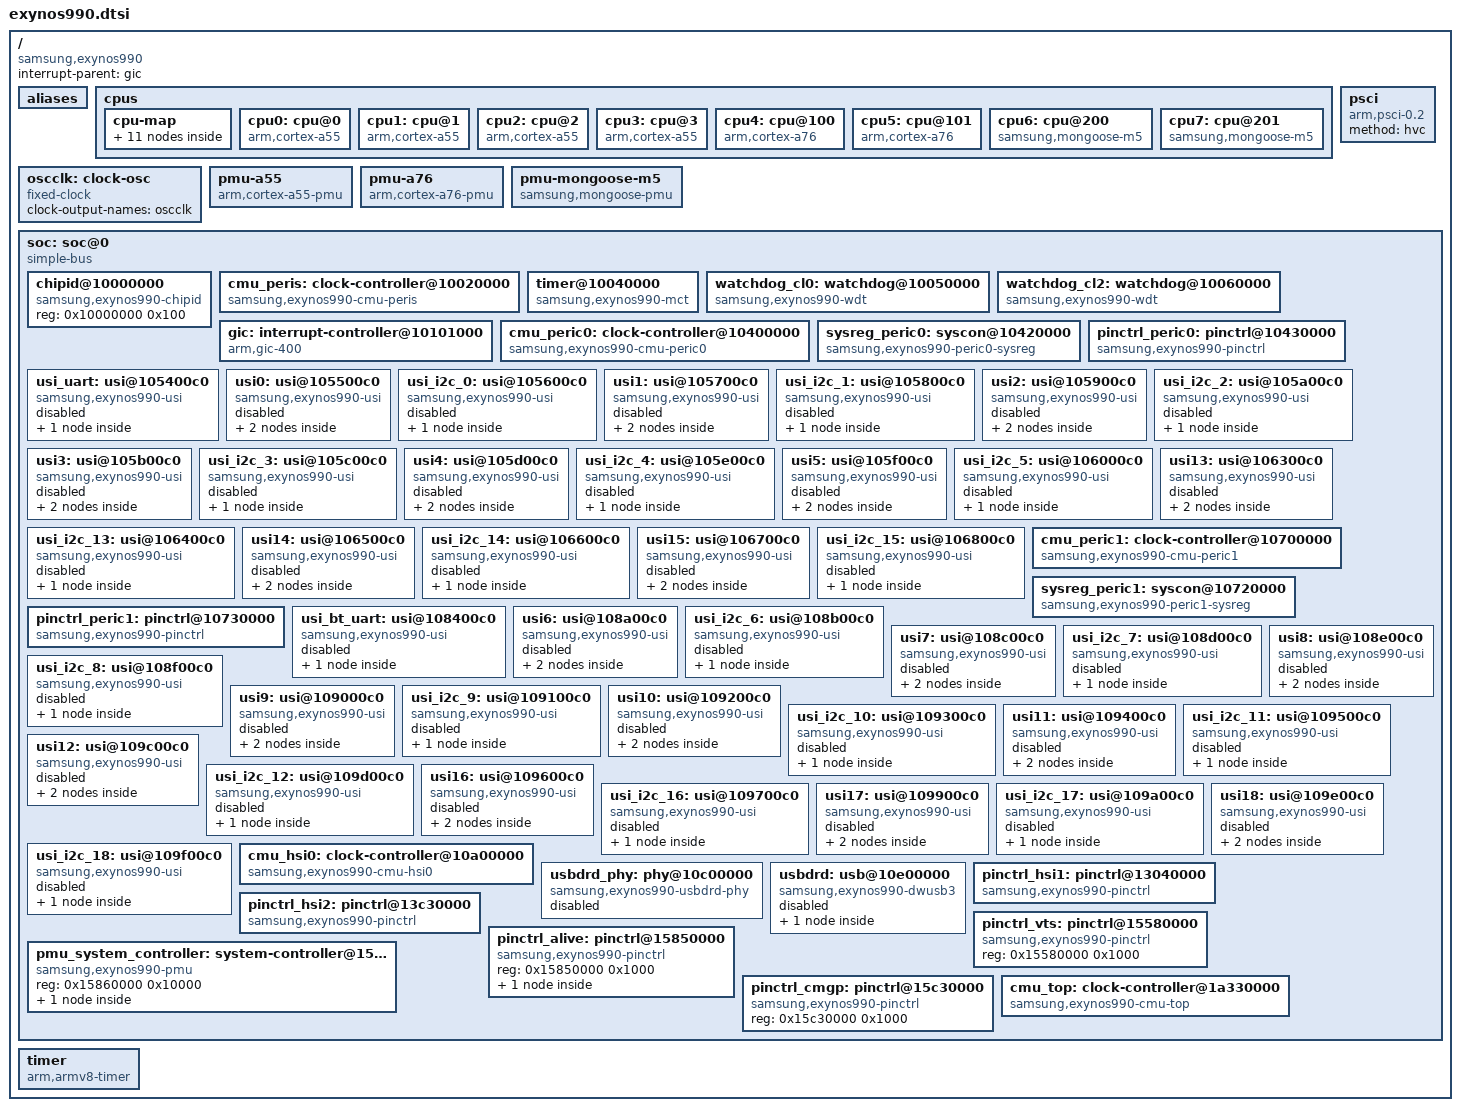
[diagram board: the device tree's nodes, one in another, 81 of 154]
// SPDX-License-Identifier: GPL-2.0 OR BSD-3-Clause
/*
 * Samsung Exynos 990 SoC device tree source
 *
 * Copyright (c) 2024, Igor Belwon <igor.belwon@mentallysanemainliners.org>
 */

#include <dt-bindings/clock/samsung,exynos990.h>
#include <dt-bindings/interrupt-controller/arm-gic.h>
#include <dt-bindings/soc/samsung,exynos-usi.h>

/ {
	compatible = "samsung,exynos990";
	#address-cells = <2>;
	#size-cells = <1>;

	interrupt-parent = <&gic>;

	aliases {
		pinctrl0 = &pinctrl_alive;
		pinctrl1 = &pinctrl_cmgp;
		pinctrl2 = &pinctrl_hsi1;
		pinctrl3 = &pinctrl_hsi2;
		pinctrl4 = &pinctrl_peric0;
		pinctrl5 = &pinctrl_peric1;
		pinctrl6 = &pinctrl_vts;
	};

	cpus {
		#address-cells = <1>;
		#size-cells = <0>;

		cpu-map {
			cluster0 {
				core0 {
					cpu = <&cpu0>;
				};

				core1 {
					cpu = <&cpu1>;
				};

				core2 {
					cpu = <&cpu2>;
				};

				core3 {
					cpu = <&cpu3>;
				};
			};

			cluster1 {
				core0 {
					cpu = <&cpu4>;
				};

				core1 {
					cpu = <&cpu5>;
				};
			};

			cluster2 {
				core0 {
					cpu = <&cpu6>;
				};

				core1 {
					cpu = <&cpu7>;
				};
			};
		};

		cpu0: cpu@0 {
			device_type = "cpu";
			compatible = "arm,cortex-a55";
			reg = <0x0>;
			enable-method = "psci";
		};

		cpu1: cpu@1 {
			device_type = "cpu";
			compatible = "arm,cortex-a55";
			reg = <0x1>;
			enable-method = "psci";
		};

		cpu2: cpu@2 {
			device_type = "cpu";
			compatible = "arm,cortex-a55";
			reg = <0x2>;
			enable-method = "psci";
		};

		cpu3: cpu@3 {
			device_type = "cpu";
			compatible = "arm,cortex-a55";
			reg = <0x3>;
			enable-method = "psci";
		};

		cpu4: cpu@100 {
			device_type = "cpu";
			compatible = "arm,cortex-a76";
			reg = <0x4>;
			enable-method = "psci";
		};

		cpu5: cpu@101 {
			device_type = "cpu";
			compatible = "arm,cortex-a76";
			reg = <0x5>;
			enable-method = "psci";
		};

		cpu6: cpu@200 {
			device_type = "cpu";
			compatible = "samsung,mongoose-m5";
			reg = <0x6>;
			enable-method = "psci";
		};

		cpu7: cpu@201 {
			device_type = "cpu";
			compatible = "samsung,mongoose-m5";
			reg = <0x7>;
			enable-method = "psci";
		};
	};

	oscclk: clock-osc {
		compatible = "fixed-clock";
		#clock-cells = <0>;
		clock-output-names = "oscclk";
	};

	pmu-a55 {
		compatible = "arm,cortex-a55-pmu";
		interrupts = <GIC_SPI 163 IRQ_TYPE_LEVEL_HIGH>,
			     <GIC_SPI 164 IRQ_TYPE_LEVEL_HIGH>,
			     <GIC_SPI 165 IRQ_TYPE_LEVEL_HIGH>,
			     <GIC_SPI 166 IRQ_TYPE_LEVEL_HIGH>;

		interrupt-affinity = <&cpu0>,
				     <&cpu1>,
				     <&cpu2>,
				     <&cpu3>;
	};

	pmu-a76 {
		compatible = "arm,cortex-a76-pmu";
		interrupts = <GIC_SPI 167 IRQ_TYPE_LEVEL_HIGH>,
			     <GIC_SPI 168 IRQ_TYPE_LEVEL_HIGH>;

		interrupt-affinity = <&cpu4>,
				     <&cpu5>;
	};

	pmu-mongoose-m5 {
		compatible = "samsung,mongoose-pmu";
		interrupts = <GIC_SPI 180 IRQ_TYPE_LEVEL_HIGH>,
			     <GIC_SPI 181 IRQ_TYPE_LEVEL_HIGH>;

		interrupt-affinity = <&cpu6>,
				     <&cpu7>;
	};

	psci {
		compatible = "arm,psci-0.2";
		method = "hvc";
	};

	soc: soc@0 {
		compatible = "simple-bus";
		ranges = <0x0 0x0 0x0 0x20000000>;

		#address-cells = <1>;
		#size-cells = <1>;

		chipid@10000000 {
			compatible = "samsung,exynos990-chipid",
				     "samsung,exynos850-chipid";
			reg = <0x10000000 0x100>;
		};

		cmu_peris: clock-controller@10020000 {
			compatible = "samsung,exynos990-cmu-peris";
			reg = <0x10020000 0x8000>;
			#clock-cells = <1>;

			clocks = <&oscclk>,
				 <&cmu_top CLK_DOUT_CMU_PERIS_BUS>;
			clock-names = "oscclk", "bus";
		};

		timer@10040000 {
			compatible = "samsung,exynos990-mct",
				     "samsung,exynos4210-mct";
			reg = <0x10040000 0x800>;
			clocks = <&oscclk>, <&cmu_peris CLK_GOUT_PERIS_MCT_PCLK>;
			clock-names = "fin_pll", "mct";
			interrupts = <GIC_SPI 466 IRQ_TYPE_LEVEL_HIGH>,
				     <GIC_SPI 467 IRQ_TYPE_LEVEL_HIGH>,
				     <GIC_SPI 468 IRQ_TYPE_LEVEL_HIGH>,
				     <GIC_SPI 469 IRQ_TYPE_LEVEL_HIGH>,
				     <GIC_SPI 470 IRQ_TYPE_LEVEL_HIGH>,
				     <GIC_SPI 471 IRQ_TYPE_LEVEL_HIGH>,
				     <GIC_SPI 472 IRQ_TYPE_LEVEL_HIGH>,
				     <GIC_SPI 473 IRQ_TYPE_LEVEL_HIGH>,
				     <GIC_SPI 474 IRQ_TYPE_LEVEL_HIGH>,
				     <GIC_SPI 475 IRQ_TYPE_LEVEL_HIGH>,
				     <GIC_SPI 476 IRQ_TYPE_LEVEL_HIGH>,
				     <GIC_SPI 477 IRQ_TYPE_LEVEL_HIGH>;
		};

		watchdog_cl0: watchdog@10050000 {
			compatible = "samsung,exynos990-wdt";
			reg = <0x10050000 0x100>;
			interrupts = <GIC_SPI 464 IRQ_TYPE_LEVEL_HIGH>;
			clocks = <&cmu_peris CLK_GOUT_PERIS_WDT_CLUSTER0_PCLK>,
				 <&oscclk>;
			clock-names = "watchdog",
				      "watchdog_src";
			samsung,syscon-phandle = <&pmu_system_controller>;
			samsung,cluster-index = <0>;
		};

		watchdog_cl2: watchdog@10060000 {
			compatible = "samsung,exynos990-wdt";
			reg = <0x10060000 0x100>;
			interrupts = <GIC_SPI 465 IRQ_TYPE_LEVEL_HIGH>;
			clocks = <&cmu_peris CLK_GOUT_PERIS_WDT_CLUSTER2_PCLK>,
				 <&oscclk>;
			clock-names = "watchdog",
				      "watchdog_src";
			samsung,syscon-phandle = <&pmu_system_controller>;
			samsung,cluster-index = <2>;
		};

		gic: interrupt-controller@10101000 {
			compatible = "arm,gic-400";
			reg = <0x10101000 0x1000>,
			      <0x10102000 0x1000>,
			      <0x10104000 0x2000>,
			      <0x10106000 0x2000>;
			#interrupt-cells = <3>;
			interrupt-controller;
			interrupts = <GIC_PPI 9 (GIC_CPU_MASK_SIMPLE(8) |
						 IRQ_TYPE_LEVEL_HIGH)>;
			#address-cells = <0>;
			#size-cells = <1>;
		};

		cmu_peric0: clock-controller@10400000 {
			compatible = "samsung,exynos990-cmu-peric0";
			reg = <0x10400000 0x8000>;
			#clock-cells = <1>;

			clocks = <&oscclk>,
				 <&cmu_top CLK_DOUT_CMU_PERIC0_BUS>,
				 <&cmu_top CLK_DOUT_CMU_PERIC0_IP>;
			clock-names = "oscclk", "bus", "ip";
		};

		sysreg_peric0: syscon@10420000 {
			compatible = "samsung,exynos990-peric0-sysreg", "syscon";
			reg = <0x10420000 0x10000>;
			clocks = <&cmu_peric0 CLK_GOUT_PERIC0_SYSREG_PCLK>;
		};

		pinctrl_peric0: pinctrl@10430000 {
			compatible = "samsung,exynos990-pinctrl";
			reg = <0x10430000 0x1000>;
			interrupts = <GIC_SPI 392 IRQ_TYPE_LEVEL_HIGH>;
		};

		usi_uart: usi@105400c0 {
			compatible = "samsung,exynos990-usi", "samsung,exynos850-usi";
			reg = <0x105400c0 0x20>;
			ranges;
			#address-cells = <1>;
			#size-cells = <1>;
			clocks = <&cmu_peric0 CLK_GOUT_PERIC0_TOP0_PCLK_4>,
				 <&cmu_peric0 CLK_GOUT_PERIC0_TOP0_IPCLK_4>;
			clock-names = "pclk", "ipclk";
			samsung,sysreg = <&sysreg_peric0 0x1000>;
			samsung,mode = <USI_MODE_UART>;
			status = "disabled";

			serial_0: serial@10540000 {
				compatible = "samsung,exynos990-uart",
					     "samsung,exynos8895-uart";
				reg = <0x10540000 0xc0>;
				clocks = <&cmu_peric0 CLK_GOUT_PERIC0_TOP0_PCLK_4>,
					 <&cmu_peric0 CLK_GOUT_PERIC0_TOP0_IPCLK_4>;
				clock-names = "uart", "clk_uart_baud0";
				interrupts = <GIC_SPI 391 IRQ_TYPE_LEVEL_HIGH>;
				pinctrl-0 = <&uart0_bus>;
				pinctrl-names = "default";
				samsung,uart-fifosize = <256>;
				status = "disabled";
			};
		};

		usi0: usi@105500c0 {
			compatible = "samsung,exynos990-usi", "samsung,exynos850-usi";
			reg = <0x105500c0 0x20>;
			ranges;
			#address-cells = <1>;
			#size-cells = <1>;
			clocks = <&cmu_peric0 CLK_GOUT_PERIC0_TOP0_PCLK_5>,
				 <&cmu_peric0 CLK_GOUT_PERIC0_TOP0_IPCLK_5>;
			clock-names = "pclk", "ipclk";
			samsung,sysreg = <&sysreg_peric0 0x1004>;
			status = "disabled";

			hsi2c_0: i2c@10550000 {
				compatible = "samsung,exynos990-hsi2c",
					     "samsung,exynosautov9-hsi2c";
				reg = <0x10550000 0xc0>;
				#address-cells = <1>;
				#size-cells = <0>;
				clocks = <&cmu_peric0 CLK_GOUT_PERIC0_TOP0_IPCLK_5>,
					 <&cmu_peric0 CLK_GOUT_PERIC0_TOP0_PCLK_5>;
				clock-names = "hsi2c", "hsi2c_pclk";
				interrupts = <GIC_SPI 399 IRQ_TYPE_LEVEL_HIGH>;
				pinctrl-0 = <&hsi2c0_bus>;
				pinctrl-names = "default";
				status = "disabled";
			};

			serial_2: serial@10550000 {
				compatible = "samsung,exynos990-uart",
					     "samsung,exynos8895-uart";
				reg = <0x10550000 0xc0>;
				clocks = <&cmu_peric0 CLK_GOUT_PERIC0_TOP0_PCLK_5>,
					 <&cmu_peric0 CLK_GOUT_PERIC0_TOP0_IPCLK_5>;
				clock-names = "uart", "clk_uart_baud0";
				interrupts = <GIC_SPI 399 IRQ_TYPE_LEVEL_HIGH>;
				pinctrl-0 = <&uart2_bus_single>;
				pinctrl-names = "default";
				samsung,uart-fifosize = <64>;
				status = "disabled";
			};
		};

		usi_i2c_0: usi@105600c0 {
			compatible = "samsung,exynos990-usi", "samsung,exynos850-usi";
			reg = <0x105600c0 0x20>;
			ranges;
			#address-cells = <1>;
			#size-cells = <1>;
			clocks = <&cmu_peric0 CLK_GOUT_PERIC0_TOP0_PCLK_6>,
				 <&cmu_peric0 CLK_GOUT_PERIC0_TOP0_IPCLK_6>;
			clock-names = "pclk", "ipclk";
			samsung,sysreg = <&sysreg_peric0 0x1008>;
			samsung,mode = <USI_MODE_I2C>;
			status = "disabled";

			hsi2c_1: i2c@10560000 {
				compatible = "samsung,exynos990-hsi2c",
					     "samsung,exynosautov9-hsi2c";
				reg = <0x10560000 0xc0>;
				#address-cells = <1>;
				#size-cells = <0>;
				clocks = <&cmu_peric0 CLK_GOUT_PERIC0_TOP0_IPCLK_6>,
					 <&cmu_peric0 CLK_GOUT_PERIC0_TOP0_PCLK_6>;
				clock-names = "hsi2c", "hsi2c_pclk";
				interrupts = <GIC_SPI 398 IRQ_TYPE_LEVEL_HIGH>;
				pinctrl-0 = <&hsi2c1_bus>;
				pinctrl-names = "default";
				status = "disabled";
			};
		};

		usi1: usi@105700c0 {
			compatible = "samsung,exynos990-usi", "samsung,exynos850-usi";
			reg = <0x105700c0 0x20>;
			ranges;
			#address-cells = <1>;
			#size-cells = <1>;
			clocks = <&cmu_peric0 CLK_GOUT_PERIC0_TOP0_PCLK_7>,
				 <&cmu_peric0 CLK_GOUT_PERIC0_TOP0_IPCLK_7>;
			clock-names = "pclk", "ipclk";
			samsung,sysreg = <&sysreg_peric0 0x100c>;
			status = "disabled";


			hsi2c_2: i2c@10570000 {
				compatible = "samsung,exynos990-hsi2c",
					     "samsung,exynosautov9-hsi2c";
				reg = <0x10570000 0xc0>;
				#address-cells = <1>;
				#size-cells = <0>;
				clocks = <&cmu_peric0 CLK_GOUT_PERIC0_TOP0_IPCLK_7>,
					 <&cmu_peric0 CLK_GOUT_PERIC0_TOP0_PCLK_7>;
				clock-names = "hsi2c", "hsi2c_pclk";
				interrupts = <GIC_SPI 401 IRQ_TYPE_LEVEL_HIGH>;
				pinctrl-0 = <&hsi2c2_bus>;
				pinctrl-names = "default";
				status = "disabled";
			};

			serial_3: serial@10570000 {
				compatible = "samsung,exynos990-uart",
					     "samsung,exynos8895-uart";
				reg = <0x10570000 0xc0>;
				clocks = <&cmu_peric0 CLK_GOUT_PERIC0_TOP0_PCLK_7>,
					 <&cmu_peric0 CLK_GOUT_PERIC0_TOP0_IPCLK_7>;
				clock-names = "uart", "clk_uart_baud0";
				interrupts = <GIC_SPI 401 IRQ_TYPE_LEVEL_HIGH>;
				pinctrl-0 = <&uart3_bus_single>;
				pinctrl-names = "default";
				samsung,uart-fifosize = <64>;
				status = "disabled";
			};
		};

		usi_i2c_1: usi@105800c0 {
			compatible = "samsung,exynos990-usi", "samsung,exynos850-usi";
			reg = <0x105800c0 0x20>;
			ranges;
			#address-cells = <1>;
			#size-cells = <1>;
			clocks = <&cmu_peric0 CLK_GOUT_PERIC0_TOP0_PCLK_8>,
				 <&cmu_peric0 CLK_GOUT_PERIC0_TOP0_IPCLK_8>;
			clock-names = "pclk", "ipclk";
			samsung,sysreg = <&sysreg_peric0 0x1010>;
			samsung,mode = <USI_MODE_I2C>;
			status = "disabled";

			hsi2c_3: i2c@10580000 {
				compatible = "samsung,exynos990-hsi2c",
					     "samsung,exynosautov9-hsi2c";
				reg = <0x10580000 0xc0>;
				#address-cells = <1>;
				#size-cells = <0>;
				clocks = <&cmu_peric0 CLK_GOUT_PERIC0_TOP0_IPCLK_8>,
					 <&cmu_peric0 CLK_GOUT_PERIC0_TOP0_PCLK_8>;
				clock-names = "hsi2c", "hsi2c_pclk";
				interrupts = <GIC_SPI 400 IRQ_TYPE_LEVEL_HIGH>;
				pinctrl-0 = <&hsi2c3_bus>;
				pinctrl-names = "default";
				status = "disabled";
			};
		};

		usi2: usi@105900c0 {
			compatible = "samsung,exynos990-usi", "samsung,exynos850-usi";
			reg = <0x105900c0 0x20>;
			ranges;
			#address-cells = <1>;
			#size-cells = <1>;
			clocks = <&cmu_peric0 CLK_GOUT_PERIC0_TOP0_PCLK_9>,
				 <&cmu_peric0 CLK_GOUT_PERIC0_TOP0_IPCLK_9>;
			clock-names = "pclk", "ipclk";
			samsung,sysreg = <&sysreg_peric0 0x1014>;
			status = "disabled";

			hsi2c_4: i2c@10590000 {
				compatible = "samsung,exynos990-hsi2c",
					     "samsung,exynosautov9-hsi2c";
				reg = <0x10590000 0xc0>;
				#address-cells = <1>;
				#size-cells = <0>;
				clocks = <&cmu_peric0 CLK_GOUT_PERIC0_TOP0_IPCLK_9>,
					 <&cmu_peric0 CLK_GOUT_PERIC0_TOP0_PCLK_9>;
				clock-names = "hsi2c", "hsi2c_pclk";
				interrupts = <GIC_SPI 403 IRQ_TYPE_LEVEL_HIGH>;
				pinctrl-0 = <&hsi2c4_bus>;
				pinctrl-names = "default";
				status = "disabled";
			};

			serial_4: serial@10590000 {
				compatible = "samsung,exynos990-uart",
					     "samsung,exynos8895-uart";
				reg = <0x10590000 0xc0>;
				clocks = <&cmu_peric0 CLK_GOUT_PERIC0_TOP0_PCLK_9>,
					 <&cmu_peric0 CLK_GOUT_PERIC0_TOP0_IPCLK_9>;
				clock-names = "uart", "clk_uart_baud0";
				interrupts = <GIC_SPI 403 IRQ_TYPE_LEVEL_HIGH>;
				pinctrl-0 = <&uart4_bus_single>;
				pinctrl-names = "default";
				samsung,uart-fifosize = <64>;
				status = "disabled";
			};
		};

		usi_i2c_2: usi@105a00c0 {
			compatible = "samsung,exynos990-usi", "samsung,exynos850-usi";
			reg = <0x105a00c0 0x20>;
			ranges;
			#address-cells = <1>;
			#size-cells = <1>;
			clocks = <&cmu_peric0 CLK_GOUT_PERIC0_TOP0_PCLK_10>,
				 <&cmu_peric0 CLK_GOUT_PERIC0_TOP0_IPCLK_10>;
			clock-names = "pclk", "ipclk";
			samsung,sysreg = <&sysreg_peric0 0x1018>;
			samsung,mode = <USI_MODE_I2C>;
			status = "disabled";

			hsi2c_5: i2c@105a0000 {
				compatible = "samsung,exynos990-hsi2c",
					     "samsung,exynosautov9-hsi2c";
				reg = <0x105a0000 0xc0>;
				#address-cells = <1>;
				#size-cells = <0>;
				clocks = <&cmu_peric0 CLK_GOUT_PERIC0_TOP0_IPCLK_10>,
					 <&cmu_peric0 CLK_GOUT_PERIC0_TOP0_PCLK_10>;
				clock-names = "hsi2c", "hsi2c_pclk";
				interrupts = <GIC_SPI 402 IRQ_TYPE_LEVEL_HIGH>;
				pinctrl-0 = <&hsi2c5_bus>;
				pinctrl-names = "default";
				status = "disabled";
			};
		};

		usi3: usi@105b00c0 {
			compatible = "samsung,exynos990-usi", "samsung,exynos850-usi";
			reg = <0x105b00c0 0x20>;
			ranges;
			#address-cells = <1>;
			#size-cells = <1>;
			clocks = <&cmu_peric0 CLK_GOUT_PERIC0_TOP0_PCLK_11>,
				 <&cmu_peric0 CLK_GOUT_PERIC0_TOP0_IPCLK_11>;
			clock-names = "pclk", "ipclk";
			samsung,sysreg = <&sysreg_peric0 0x101c>;
			status = "disabled";

			hsi2c_6: i2c@105b0000 {
				compatible = "samsung,exynos990-hsi2c",
					     "samsung,exynosautov9-hsi2c";
				reg = <0x105b0000 0xc0>;
				#address-cells = <1>;
				#size-cells = <0>;
				clocks = <&cmu_peric0 CLK_GOUT_PERIC0_TOP0_IPCLK_11>,
					 <&cmu_peric0 CLK_GOUT_PERIC0_TOP0_PCLK_11>;
				clock-names = "hsi2c", "hsi2c_pclk";
				interrupts = <GIC_SPI 405 IRQ_TYPE_LEVEL_HIGH>;
				pinctrl-0 = <&hsi2c6_bus>;
				pinctrl-names = "default";
				status = "disabled";
			};

			serial_5: serial@105b0000 {
				compatible = "samsung,exynos990-uart",
					     "samsung,exynos8895-uart";
				reg = <0x105b0000 0xc0>;
				clocks = <&cmu_peric0 CLK_GOUT_PERIC0_TOP0_PCLK_11>,
					 <&cmu_peric0 CLK_GOUT_PERIC0_TOP0_IPCLK_11>;
				clock-names = "uart", "clk_uart_baud0";
				interrupts = <GIC_SPI 405 IRQ_TYPE_LEVEL_HIGH>;
				pinctrl-0 = <&uart5_bus_single>;
				pinctrl-names = "default";
				samsung,uart-fifosize = <64>;
				status = "disabled";
			};
		};

		usi_i2c_3: usi@105c00c0 {
			compatible = "samsung,exynos990-usi", "samsung,exynos850-usi";
			reg = <0x105c00c0 0x20>;
			ranges;
			#address-cells = <1>;
			#size-cells = <1>;
			clocks = <&cmu_peric0 CLK_GOUT_PERIC0_TOP0_PCLK_12>,
				 <&cmu_peric0 CLK_GOUT_PERIC0_TOP0_IPCLK_12>;
			clock-names = "pclk", "ipclk";
			samsung,sysreg = <&sysreg_peric0 0x1020>;
			samsung,mode = <USI_MODE_I2C>;
			status = "disabled";

			hsi2c_7: i2c@105c0000 {
				compatible = "samsung,exynos990-hsi2c",
					     "samsung,exynosautov9-hsi2c";
				reg = <0x105c0000 0xc0>;
				#address-cells = <1>;
				#size-cells = <0>;
				clocks = <&cmu_peric0 CLK_GOUT_PERIC0_TOP0_IPCLK_12>,
					 <&cmu_peric0 CLK_GOUT_PERIC0_TOP0_PCLK_12>;
				clock-names = "hsi2c", "hsi2c_pclk";
				interrupts = <GIC_SPI 404 IRQ_TYPE_LEVEL_HIGH>;
				pinctrl-0 = <&hsi2c7_bus>;
				pinctrl-names = "default";
				status = "disabled";
			};
		};

		usi4: usi@105d00c0 {
			compatible = "samsung,exynos990-usi", "samsung,exynos850-usi";
			reg = <0x105d00c0 0x20>;
			ranges;
			#address-cells = <1>;
			#size-cells = <1>;
			clocks = <&cmu_peric0 CLK_GOUT_PERIC0_TOP0_PCLK_13>,
				 <&cmu_peric0 CLK_GOUT_PERIC0_TOP0_IPCLK_13>;
			clock-names = "pclk", "ipclk";
			samsung,sysreg = <&sysreg_peric0 0x1024>;
			status = "disabled";

			hsi2c_8: i2c@105d0000 {
				compatible = "samsung,exynos990-hsi2c",
					     "samsung,exynosautov9-hsi2c";
				reg = <0x105d0000 0xc0>;
				#address-cells = <1>;
				#size-cells = <0>;
				clocks = <&cmu_peric0 CLK_GOUT_PERIC0_TOP0_IPCLK_13>,
					 <&cmu_peric0 CLK_GOUT_PERIC0_TOP0_PCLK_13>;
				clock-names = "hsi2c", "hsi2c_pclk";
				interrupts = <GIC_SPI 407 IRQ_TYPE_LEVEL_HIGH>;
				pinctrl-0 = <&hsi2c8_bus>;
				pinctrl-names = "default";
				status = "disabled";
			};

			serial_6: serial@105d0000 {
				compatible = "samsung,exynos990-uart",
					     "samsung,exynos8895-uart";
				reg = <0x105d0000 0xc0>;
				clocks = <&cmu_peric0 CLK_GOUT_PERIC0_TOP0_PCLK_13>,
					 <&cmu_peric0 CLK_GOUT_PERIC0_TOP0_IPCLK_13>;
				clock-names = "uart", "clk_uart_baud0";
				interrupts = <GIC_SPI 407 IRQ_TYPE_LEVEL_HIGH>;
				pinctrl-0 = <&uart6_bus_single>;
				pinctrl-names = "default";
				samsung,uart-fifosize = <64>;
				status = "disabled";
			};
		};

		usi_i2c_4: usi@105e00c0 {
			compatible = "samsung,exynos990-usi", "samsung,exynos850-usi";
			reg = <0x105e00c0 0x20>;
			ranges;
			#address-cells = <1>;
			#size-cells = <1>;
			clocks = <&cmu_peric0 CLK_GOUT_PERIC0_TOP0_PCLK_14>,
				 <&cmu_peric0 CLK_GOUT_PERIC0_TOP0_IPCLK_14>;
			clock-names = "pclk", "ipclk";
			samsung,sysreg = <&sysreg_peric0 0x1028>;
			samsung,mode = <USI_MODE_I2C>;
			status = "disabled";

			hsi2c_9: i2c@105e0000 {
				compatible = "samsung,exynos990-hsi2c",
					     "samsung,exynosautov9-hsi2c";
				reg = <0x105e0000 0xc0>;
				#address-cells = <1>;
				#size-cells = <0>;
				clocks = <&cmu_peric0 CLK_GOUT_PERIC0_TOP0_IPCLK_14>,
					 <&cmu_peric0 CLK_GOUT_PERIC0_TOP0_PCLK_14>;
				clock-names = "hsi2c", "hsi2c_pclk";
				interrupts = <GIC_SPI 406 IRQ_TYPE_LEVEL_HIGH>;
				pinctrl-0 = <&hsi2c9_bus>;
				pinctrl-names = "default";
				status = "disabled";
			};
		};

		usi5: usi@105f00c0 {
			compatible = "samsung,exynos990-usi", "samsung,exynos850-usi";
			reg = <0x105f00c0 0x20>;
			ranges;
			#address-cells = <1>;
			#size-cells = <1>;
			clocks = <&cmu_peric0 CLK_GOUT_PERIC0_TOP0_PCLK_15>,
				 <&cmu_peric0 CLK_GOUT_PERIC0_TOP0_IPCLK_15>;
			clock-names = "pclk", "ipclk";
			samsung,sysreg = <&sysreg_peric0 0x102c>;
			status = "disabled";

			hsi2c_10: i2c@105f0000 {
				compatible = "samsung,exynos990-hsi2c",
					     "samsung,exynosautov9-hsi2c";
				reg = <0x105f0000 0xc0>;
				#address-cells = <1>;
				#size-cells = <0>;
				clocks = <&cmu_peric0 CLK_GOUT_PERIC0_TOP0_IPCLK_15>,
					 <&cmu_peric0 CLK_GOUT_PERIC0_TOP0_PCLK_15>;
				clock-names = "hsi2c", "hsi2c_pclk";
				interrupts = <GIC_SPI 409 IRQ_TYPE_LEVEL_HIGH>;
				pinctrl-0 = <&hsi2c10_bus>;
				pinctrl-names = "default";
				status = "disabled";
			};

			serial_7: serial@105f0000 {
				compatible = "samsung,exynos990-uart",
					     "samsung,exynos8895-uart";
				reg = <0x105f0000 0xc0>;
				clocks = <&cmu_peric0 CLK_GOUT_PERIC0_TOP0_PCLK_15>,
					 <&cmu_peric0 CLK_GOUT_PERIC0_TOP0_IPCLK_15>;
				clock-names = "uart", "clk_uart_baud0";
				interrupts = <GIC_SPI 409 IRQ_TYPE_LEVEL_HIGH>;
				pinctrl-0 = <&uart7_bus_single>;
				pinctrl-names = "default";
				samsung,uart-fifosize = <64>;
				status = "disabled";
			};
		};

		usi_i2c_5: usi@106000c0 {
			compatible = "samsung,exynos990-usi", "samsung,exynos850-usi";
			reg = <0x106000c0 0x20>;
			rsnges;
			#address-cells = <1>;
			#size-cells = <1>;
			clocks = <&cmu_peric0 CLK_GOUT_PERIC0_TOP1_PCLK_0>,
				 <&cmu_peric0 CLK_GOUT_PERIC0_TOP1_IPCLK_0>;
			clock-names = "pclk", "ipclk";
			samsung,sysreg = <&sysreg_peric0 0x1030>;
			samsung,mode = <USI_MODE_I2C>;
			status = "disabled";

			hsi2c_11: i2c@10600000 {
				compatible = "samsung,exynos990-hsi2c",
					     "samsung,exynosautov9-hsi2c";
				reg = <0x10600000 0xc0>;
				#address-cells = <1>;
				#size-cells = <0>;
				interrupts = <GIC_SPI 408 IRQ_TYPE_LEVEL_HIGH>;
				clocks = <&cmu_peric0 CLK_GOUT_PERIC0_TOP1_IPCLK_0>,
					 <&cmu_peric0 CLK_GOUT_PERIC0_TOP1_PCLK_0>;
				clock-names = "hsi2c", "hsi2c_pclk";
				pinctrl-0 = <&hsi2c11_bus>;
				pinctrl-names = "default";
				status = "disabled";
			};
		};

		usi13: usi@106300c0 {
			compatible = "samsung,exynos990-usi", "samsung,exynos850-usi";
			reg = <0x106300c0 0x20>;
			ranges;
			#address-cells = <1>;
			#size-cells = <1>;
			clocks = <&cmu_peric0 CLK_GOUT_PERIC0_TOP1_PCLK_3>,
				 <&cmu_peric0 CLK_GOUT_PERIC0_TOP1_IPCLK_3>;
			clock-names = "pclk", "ipclk";
			samsung,sysreg = <&sysreg_peric0 0x103c>;
			status = "disabled";

			hsi2c_26: i2c@10630000 {
				compatible = "samsung,exynos990-hsi2c",
					     "samsung,exynosautov9-hsi2c";
				reg = <0x10630000 0xc0>;
				#address-cells = <1>;
				#size-cells = <0>;
				clocks = <&cmu_peric0 CLK_GOUT_PERIC0_TOP1_IPCLK_3>,
					 <&cmu_peric0 CLK_GOUT_PERIC0_TOP1_PCLK_3>;
				clock-names = "hsi2c", "hsi2c_pclk";
				interrupts = <GIC_SPI 411 IRQ_TYPE_LEVEL_HIGH>;
				pinctrl-0 = <&hsi2c26_bus>;
				pinctrl-names = "default";
				status = "disabled";
			};

			serial_15: serial@10630000 {
				compatible = "samsung,exynos990-uart",
					     "samsung,exynos8895-uart";
				reg = <0x10630000 0xc0>;
				clocks = <&cmu_peric0 CLK_GOUT_PERIC0_TOP1_PCLK_3>,
					 <&cmu_peric0 CLK_GOUT_PERIC0_TOP1_IPCLK_3>;
				clock-names = "uart", "clk_uart_baud0";
				interrupts = <GIC_SPI 411 IRQ_TYPE_LEVEL_HIGH>;
				pinctrl-0 = <&uart15_bus_single>;
				pinctrl-names = "default";
				samsung,uart-fifosize = <64>;
				status = "disabled";
			};
		};

		usi_i2c_13: usi@106400c0 {
			compatible = "samsung,exynos990-usi", "samsung,exynos850-usi";
			reg = <0x106400c0 0x20>;
			ranges;
			#address-cells = <1>;
			#size-cells = <1>;
			clocks = <&cmu_peric0 CLK_GOUT_PERIC0_TOP1_PCLK_4>,
				 <&cmu_peric0 CLK_GOUT_PERIC0_TOP1_IPCLK_4>;
			clock-names = "pclk", "ipclk";
			samsung,sysreg = <&sysreg_peric0 0x1040>;
			samsung,mode = <USI_MODE_I2C>;
			status = "disabled";

			hsi2c_27: i2c@10640000 {
				compatible = "samsung,exynos990-hsi2c",
					     "samsung,exynosautov9-hsi2c";
				reg = <0x10640000 0xc0>;
				#address-cells = <1>;
				#size-cells = <0>;
				clocks = <&cmu_peric0 CLK_GOUT_PERIC0_TOP1_IPCLK_4>,
					 <&cmu_peric0 CLK_GOUT_PERIC0_TOP1_PCLK_4>;
				clock-names = "hsi2c", "hsi2c_pclk";
				interrupts = <GIC_SPI 410 IRQ_TYPE_LEVEL_HIGH>;
				pinctrl-0 = <&hsi2c27_bus>;
				pinctrl-names = "default";
				status = "disabled";
			};
		};

		usi14: usi@106500c0 {
			compatible = "samsung,exynos990-usi", "samsung,exynos850-usi";
			reg = <0x106500c0 0x20>;
			ranges;
			#address-cells = <1>;
			#size-cells = <1>;
			clocks = <&cmu_peric0 CLK_GOUT_PERIC0_TOP1_PCLK_5>,
				 <&cmu_peric0 CLK_GOUT_PERIC0_TOP1_IPCLK_5>;
			clock-names = "pclk", "ipclk";
			samsung,sysreg = <&sysreg_peric0 0x1044>;
			status = "disabled";

			hsi2c_28: i2c@10650000 {
				compatible = "samsung,exynos990-hsi2c",
					     "samsung,exynosautov9-hsi2c";
				reg = <0x10650000 0xc0>;
				#address-cells = <1>;
				#size-cells = <0>;
				clocks = <&cmu_peric0 CLK_GOUT_PERIC0_TOP1_IPCLK_5>,
					 <&cmu_peric0 CLK_GOUT_PERIC0_TOP1_PCLK_5>;
				clock-names = "hsi2c", "hsi2c_pclk";
				interrupts = <GIC_SPI 413 IRQ_TYPE_LEVEL_HIGH>;
				pinctrl-0 = <&hsi2c28_bus>;
				pinctrl-names = "default";
				status = "disabled";
			};

			serial_16: serial@10650000 {
				compatible = "samsung,exynos990-uart",
					     "samsung,exynos8895-uart";
				reg = <0x10650000 0xc0>;
				clocks = <&cmu_peric0 CLK_GOUT_PERIC0_TOP1_PCLK_5>,
					 <&cmu_peric0 CLK_GOUT_PERIC0_TOP1_IPCLK_5>;
				clock-names = "uart", "clk_uart_baud0";
				interrupts = <GIC_SPI 413 IRQ_TYPE_LEVEL_HIGH>;
				pinctrl-0 = <&uart16_bus_single>;
				pinctrl-names = "default";
				samsung,uart-fifosize = <64>;
				status = "disabled";
			};
		};

		usi_i2c_14: usi@106600c0 {
			compatible = "samsung,exynos990-usi", "samsung,exynos850-usi";
			reg = <0x106600c0 0x20>;
			ranges;
			#address-cells = <1>;
			#size-cells = <1>;
			clocks = <&cmu_peric0 CLK_GOUT_PERIC0_TOP1_PCLK_0>,
				 <&cmu_peric0 CLK_GOUT_PERIC0_TOP1_IPCLK_0>;
			clock-names = "pclk", "ipclk";
			samsung,sysreg = <&sysreg_peric0 0x1048>;
			samsung,mode = <USI_MODE_I2C>;
			status = "disabled";

			hsi2c_29: i2c@10660000 {
				compatible = "samsung,exynos990-hsi2c",
					     "samsung,exynosautov9-hsi2c";
				reg = <0x10660000 0xc0>;
				#address-cells = <1>;
				#size-cells = <0>;
				clocks = <&cmu_peric0 CLK_GOUT_PERIC0_TOP1_IPCLK_6>,
					 <&cmu_peric0 CLK_GOUT_PERIC0_TOP1_PCLK_6>;
				clock-names = "hsi2c", "hsi2c_pclk";
				interrupts = <GIC_SPI 412 IRQ_TYPE_LEVEL_HIGH>;
				pinctrl-0 = <&hsi2c29_bus>;
				pinctrl-names = "default";
				status = "disabled";
			};
		};

		usi15: usi@106700c0 {
			compatible = "samsung,exynos990-usi", "samsung,exynos850-usi";
			reg = <0x106700c0 0x20>;
			ranges;
			#address-cells = <1>;
			#size-cells = <1>;
			clocks = <&cmu_peric0 CLK_GOUT_PERIC0_TOP1_PCLK_7>,
				 <&cmu_peric0 CLK_GOUT_PERIC0_TOP1_IPCLK_7>;
			clock-names = "pclk", "ipclk";
			samsung,sysreg = <&sysreg_peric0 0x104c>;
			status = "disabled";

			hsi2c_30: i2c@10670000 {
				compatible = "samsung,exynos990-hsi2c",
					     "samsung,exynosautov9-hsi2c";
				reg = <0x10670000 0xc0>;
				#address-cells = <1>;
				#size-cells = <0>;
				clocks = <&cmu_peric0 CLK_GOUT_PERIC0_TOP1_IPCLK_7>,
					 <&cmu_peric0 CLK_GOUT_PERIC0_TOP1_PCLK_7>;
				clock-names = "hsi2c", "hsi2c_pclk";
				interrupts = <GIC_SPI 415 IRQ_TYPE_LEVEL_HIGH>;
				pinctrl-0 = <&hsi2c30_bus>;
				pinctrl-names = "default";
				status = "disabled";
			};

			serial_17: serial@10670000 {
				compatible = "samsung,exynos990-uart",
					     "samsung,exynos8895-uart";
				reg = <0x10670000 0xc0>;
				clocks = <&cmu_peric0 CLK_GOUT_PERIC0_TOP1_PCLK_7>,
					 <&cmu_peric0 CLK_GOUT_PERIC0_TOP1_IPCLK_7>;
				clock-names = "uart", "clk_uart_baud0";
				interrupts = <GIC_SPI 415 IRQ_TYPE_LEVEL_HIGH>;
				pinctrl-0 = <&uart17_bus_single>;
				pinctrl-names = "default";
				samsung,uart-fifosize = <64>;
				status = "disabled";
			};
		};

		usi_i2c_15: usi@106800c0 {
			compatible = "samsung,exynos990-usi", "samsung,exynos850-usi";
			reg = <0x106800c0 0x20>;
			ranges;
			#address-cells = <1>;
			#size-cells = <1>;
			clocks = <&cmu_peric0 CLK_GOUT_PERIC0_TOP1_PCLK_8>,
				 <&cmu_peric0 CLK_GOUT_PERIC0_TOP1_IPCLK_8>;
			clock-names = "pclk", "ipclk";
			samsung,sysreg = <&sysreg_peric0 0x1050>;
			samsung,mode = <USI_MODE_I2C>;
			status = "disabled";

			hsi2c_31: i2c@10680000 {
				compatible = "samsung,exynos990-hsi2c",
					     "samsung,exynosautov9-hsi2c";
				reg = <0x10680000 0xc0>;
				#address-cells = <1>;
				#size-cells = <0>;
				clocks = <&cmu_peric0 CLK_GOUT_PERIC0_TOP1_IPCLK_8>,
					 <&cmu_peric0 CLK_GOUT_PERIC0_TOP1_PCLK_8>;
				clock-names = "hsi2c", "hsi2c_pclk";
				interrupts = <GIC_SPI 414 IRQ_TYPE_LEVEL_HIGH>;
				pinctrl-0 = <&hsi2c31_bus>;
				inctrl-names = "default";
				status = "disabled";
			};
		};

		cmu_peric1: clock-controller@10700000 {
			compatible = "samsung,exynos990-cmu-peric1";
			reg = <0x10700000 0x8000>;
			#clock-cells = <1>;

			clocks = <&oscclk>,
				 <&cmu_top CLK_DOUT_CMU_PERIC1_BUS>,
				 <&cmu_top CLK_DOUT_CMU_PERIC1_IP>;
			clock-names = "oscclk", "bus", "ip";
		};

		sysreg_peric1: syscon@10720000 {
			compatible = "samsung,exynos990-peric1-sysreg", "syscon";
			reg = <0x10720000 0x10000>;
			clocks = <&cmu_peric1 CLK_GOUT_PERIC1_SYSREG_PCLK>;
		};

		pinctrl_peric1: pinctrl@10730000 {
			compatible = "samsung,exynos990-pinctrl";
			reg = <0x10730000 0x1000>;
			interrupts = <GIC_SPI 417 IRQ_TYPE_LEVEL_HIGH>;
		};

		usi_bt_uart: usi@108400c0 {
			compatible = "samsung,exynos990-usi", "samsung,exynos850-usi";
			reg = <0x108400c0 0x20>;
			ranges;
			#address-cells = <1>;
			#size-cells = <1>;
			clocks = <&cmu_peric1 CLK_GOUT_PERIC1_TOP0_PCLK_4>,
				 <&cmu_peric1 CLK_GOUT_PERIC1_TOP0_IPCLK_4>;
			clock-names = "pclk", "ipclk";
			samsung,sysreg = <&sysreg_peric1 0x1000>;
			samsung,mode = <USI_MODE_UART>;
			status = "disabled";

			serial_1: serial@10840000 {
				compatible = "samsung,exynos990-uart",
					     "samsung,exynos8895-uart";
				reg = <0x10840000 0xc0>;
				clocks = <&cmu_peric1 CLK_GOUT_PERIC1_TOP0_PCLK_4>,
					 <&cmu_peric1 CLK_GOUT_PERIC1_TOP0_IPCLK_4>;
				clock-names = "uart", "clk_uart_baud0";
				interrupts = <GIC_SPI 416 IRQ_TYPE_LEVEL_HIGH>;
				pinctrl-0 = <&uart1_bus_single>;
				pinctrl-names = "default";
				samsung,uart-fifosize = <256>;
				status = "disabled";
			};
		};

		usi6: usi@108a00c0 {
			compatible = "samsung,exynos990-usi", "samsung,exynos850-usi";
			reg = <0x108a00c0 0x20>;
			ranges;
			#address-cells = <1>;
			#size-cells = <1>;
			clocks = <&cmu_peric1 CLK_GOUT_PERIC1_TOP0_PCLK_10>,
				 <&cmu_peric1 CLK_GOUT_PERIC1_TOP0_IPCLK_10>;
			clock-names = "pclk", "ipclk";
			samsung,sysreg = <&sysreg_peric1 0x1018>;
			status = "disabled";

			hsi2c_12: i2c@108a0000 {
				compatible = "samsung,exynos990-hsi2c",
					     "samsung,exynosautov9-hsi2c";
				reg = <0x108a0000 0xc0>;
				#address-cells = <1>;
				#size-cells = <0>;
				clocks = <&cmu_peric1 CLK_GOUT_PERIC1_TOP0_IPCLK_10>,
					 <&cmu_peric1 CLK_GOUT_PERIC1_TOP0_PCLK_10>;
				clock-names = "hsi2c", "hsi2c_pclk";
				interrupts = <GIC_SPI 419 IRQ_TYPE_LEVEL_HIGH>;
				pinctrl-0 = <&hsi2c12_bus>;
				pinctrl-names = "default";
				status = "disabled";
			};

			serial_8: serial@108a0000 {
				compatible = "samsung,exynos990-uart",
					     "samsung,exynos8895-uart";
				reg = <0x108a0000 0xc0>;
				clocks = <&cmu_peric1 CLK_GOUT_PERIC1_TOP0_PCLK_10>,
					 <&cmu_peric1 CLK_GOUT_PERIC1_TOP0_IPCLK_10>;
				clock-names = "uart", "clk_uart_baud0";
				interrupts = <GIC_SPI 419 IRQ_TYPE_LEVEL_HIGH>;
				pinctrl-0 = <&uart8_bus_single>;
				pinctrl-names = "default";
				samsung,uart-fifosize = <64>;
				status = "disabled";
			};
		};

		usi_i2c_6: usi@108b00c0 {
			compatible = "samsung,exynos990-usi", "samsung,exynos850-usi";
			reg = <0x108b00c0 0x20>;
			ranges;
			#address-cells = <1>;
			#size-cells = <1>;
			clocks = <&cmu_peric1 CLK_GOUT_PERIC1_TOP0_PCLK_11>,
				 <&cmu_peric1 CLK_GOUT_PERIC1_TOP0_IPCLK_11>;
			clock-names = "pclk", "ipclk";
			samsung,sysreg = <&sysreg_peric1 0x101c>;
			samsung,mode = <USI_MODE_I2C>;
			status = "disabled";

			hsi2c_13: i2c@108b0000 {
				compatible = "samsung,exynos990-hsi2c",
					     "samsung,exynosautov9-hsi2c";
				reg = <0x108b0000 0xc0>;
				#address-cells = <1>;
				#size-cells = <0>;
				clocks = <&cmu_peric1 CLK_GOUT_PERIC1_TOP0_IPCLK_11>,
					 <&cmu_peric1 CLK_GOUT_PERIC1_TOP0_PCLK_11>;
				clock-names = "hsi2c", "hsi2c_pclk";
				interrupts = <GIC_SPI 418 IRQ_TYPE_LEVEL_HIGH>;
				pinctrl-0 = <&hsi2c13_bus>;
				pinctrl-names = "default";
				status = "disabled";
			};
		};

		usi7: usi@108c00c0 {
			compatible = "samsung,exynos990-usi", "samsung,exynos850-usi";
			reg = <0x108c00c0 0x20>;
			ranges;
			#address-cells = <1>;
			#size-cells = <1>;
			clocks = <&cmu_peric1 CLK_GOUT_PERIC1_TOP0_PCLK_12>,
				 <&cmu_peric1 CLK_GOUT_PERIC1_TOP0_IPCLK_12>;
			clock-names = "pclk", "ipclk";
			samsung,sysreg = <&sysreg_peric1 0x1020>;
			status = "disabled";

			hsi2c_14: i2c@108c0000 {
				compatible = "samsung,exynos990-hsi2c",
					     "samsung,exynosautov9-hsi2c";
				reg = <0x108c0000 0xc0>;
				#address-cells = <1>;
				#size-cells = <0>;
				clocks = <&cmu_peric1 CLK_GOUT_PERIC1_TOP0_IPCLK_12>,
					 <&cmu_peric1 CLK_GOUT_PERIC1_TOP0_PCLK_12>;
				clock-names = "hsi2c", "hsi2c_pclk";
				interrupts = <GIC_SPI 421 IRQ_TYPE_LEVEL_HIGH>;
				pinctrl-0 = <&hsi2c14_bus>;
				pinctrl-names = "default";
				status = "disabled";
			};

			serial_9: serial@108c0000 {
				compatible = "samsung,exynos990-uart",
					     "samsung,exynos8895-uart";
				reg = <0x108c0000 0xc0>;
				clocks = <&cmu_peric1 CLK_GOUT_PERIC1_TOP0_PCLK_12>,
					 <&cmu_peric1 CLK_GOUT_PERIC1_TOP0_IPCLK_12>;
				clock-names = "uart", "clk_uart_baud0";
				interrupts = <GIC_SPI 421 IRQ_TYPE_LEVEL_HIGH>;
				pinctrl-0 = <&uart9_bus_single>;
				pinctrl-names = "default";
				samsung,uart-fifosize = <64>;
				status = "disabled";
			};
		};

		usi_i2c_7: usi@108d00c0 {
			compatible = "samsung,exynos990-usi", "samsung,exynos850-usi";
			reg = <0x108d00c0 0x20>;
			ranges;
			#address-cells = <1>;
			#size-cells = <1>;
			clocks = <&cmu_peric1 CLK_GOUT_PERIC1_TOP0_PCLK_13>,
				 <&cmu_peric1 CLK_GOUT_PERIC1_TOP0_IPCLK_13>;
			clock-names = "pclk", "ipclk";
			samsung,sysreg = <&sysreg_peric1 0x1024>;
			samsung,mode = <USI_MODE_I2C>;
			status = "disabled";

			hsi2c_15: i2c@108d0000 {
				compatible = "samsung,exynos990-hsi2c",
					     "samsung,exynosautov9-hsi2c";
				reg = <0x108d0000 0xc0>;
				#address-cells = <1>;
				#size-cells = <0>;
				clocks = <&cmu_peric1 CLK_GOUT_PERIC1_TOP0_IPCLK_13>,
					 <&cmu_peric1 CLK_GOUT_PERIC1_TOP0_PCLK_13>;
				clock-names = "hsi2c", "hsi2c_pclk";
				interrupts = <GIC_SPI 420 IRQ_TYPE_LEVEL_HIGH>;
				pinctrl-0 = <&hsi2c15_bus>;
				pinctrl-names = "default";
				status = "disabled";
			};
		};

		usi8: usi@108e00c0 {
			compatible = "samsung,exynos990-usi", "samsung,exynos850-usi";
			reg = <0x108e00c0 0x20>;
			ranges;
			#address-cells = <1>;
			#size-cells = <1>;
			clocks = <&cmu_peric1 CLK_GOUT_PERIC1_TOP0_PCLK_14>,
				 <&cmu_peric1 CLK_GOUT_PERIC1_TOP0_IPCLK_14>;
			clock-names = "pclk", "ipclk";
			samsung,sysreg = <&sysreg_peric1 0x1028>;
			status = "disabled";

			hsi2c_16: i2c@108e0000 {
				compatible = "samsung,exynos990-hsi2c",
					     "samsung,exynosautov9-hsi2c";
				reg = <0x108e0000 0xc0>;
				#address-cells = <1>;
				#size-cells = <0>;
				clocks = <&cmu_peric1 CLK_GOUT_PERIC1_TOP0_IPCLK_14>,
					 <&cmu_peric1 CLK_GOUT_PERIC1_TOP0_PCLK_14>;
				clock-names = "hsi2c", "hsi2c_pclk";
				interrupts = <GIC_SPI 423 IRQ_TYPE_LEVEL_HIGH>;
				pinctrl-0 = <&hsi2c16_bus>;
				pinctrl-names = "default";
				status = "disabled";
			};

			serial_10: serial@108e0000 {
				compatible = "samsung,exynos990-uart",
					     "samsung,exynos8895-uart";
				reg = <0x108e0000 0xc0>;
				clocks = <&cmu_peric1 CLK_GOUT_PERIC1_TOP0_PCLK_14>,
					 <&cmu_peric1 CLK_GOUT_PERIC1_TOP0_IPCLK_14>;
				clock-names = "uart", "clk_uart_baud0";
				interrupts = <GIC_SPI 423 IRQ_TYPE_LEVEL_HIGH>;
				pinctrl-0 = <&uart10_bus_single>;
				pinctrl-names = "default";
				samsung,uart-fifosize = <256>;
				status = "disabled";
			};
		};

		usi_i2c_8: usi@108f00c0 {
			compatible = "samsung,exynos990-usi", "samsung,exynos850-usi";
			reg = <0x108f00c0 0x20>;
			ranges;
			#address-cells = <1>;
			#size-cells = <1>;
			clocks = <&cmu_peric1 CLK_GOUT_PERIC1_TOP0_PCLK_15>,
				 <&cmu_peric1 CLK_GOUT_PERIC1_TOP0_IPCLK_15>;
			clock-names = "pclk", "ipclk";
			samsung,sysreg = <&sysreg_peric1 0x102c>;
			samsung,mode = <USI_MODE_I2C>;
			status = "disabled";

			hsi2c_17: i2c@108f0000 {
				compatible = "samsung,exynos990-hsi2c",
					     "samsung,exynosautov9-hsi2c";
				reg = <0x108f0000 0xc0>;
				#address-cells = <1>;
				#size-cells = <0>;
				clocks = <&cmu_peric1 CLK_GOUT_PERIC1_TOP0_IPCLK_15>,
					 <&cmu_peric1 CLK_GOUT_PERIC1_TOP0_PCLK_15>;
				clock-names = "hsi2c", "hsi2c_pclk";
				interrupts = <GIC_SPI 422 IRQ_TYPE_LEVEL_HIGH>;
				pinctrl-0 = <&hsi2c17_bus>;
				pinctrl-names = "default";
				status = "disabled";
			};
		};

		usi9: usi@109000c0 {
			compatible = "samsung,exynos990-usi", "samsung,exynos850-usi";
			reg = <0x109000c0 0x20>;
			ranges;
			#address-cells = <1>;
			#size-cells = <1>;
			clocks = <&cmu_peric1 CLK_GOUT_PERIC1_TOP1_PCLK_0>,
				 <&cmu_peric1 CLK_GOUT_PERIC1_TOP1_IPCLK_0>;
			clock-names = "pclk", "ipclk";
			samsung,sysreg = <&sysreg_peric1 0x1030>;
			status = "disabled";

			hsi2c_18: i2c@10900000 {
				compatible = "samsung,exynos990-hsi2c",
					     "samsung,exynosautov9-hsi2c";
				reg = <0x10900000 0xc0>;
				#address-cells = <1>;
				#size-cells = <0>;
				clocks = <&cmu_peric1 CLK_GOUT_PERIC1_TOP1_IPCLK_0>,
					 <&cmu_peric1 CLK_GOUT_PERIC1_TOP1_PCLK_0>;
				clock-names = "hsi2c", "hsi2c_pclk";
				interrupts = <GIC_SPI 425 IRQ_TYPE_LEVEL_HIGH>;
				pinctrl-0 = <&hsi2c18_bus>;
				pinctrl-names = "default";
				status = "disabled";
			};

			serial_11: serial@10900000 {
				compatible = "samsung,exynos990-uart",
					     "samsung,exynos8895-uart";
				reg = <0x10900000 0xc0>;
				clocks = <&cmu_peric1 CLK_GOUT_PERIC1_TOP1_PCLK_0>,
					 <&cmu_peric1 CLK_GOUT_PERIC1_TOP1_IPCLK_0>;
				clock-names = "uart", "clk_uart_baud0";
				interrupts = <GIC_SPI 425 IRQ_TYPE_LEVEL_HIGH>;
				pinctrl-0 = <&uart11_bus_single>;
				pinctrl-names = "default";
				samsung,uart-fifosize = <256>;
				status = "disabled";
			};
		};

		usi_i2c_9: usi@109100c0 {
			compatible = "samsung,exynos990-usi", "samsung,exynos850-usi";
			reg = <0x109100c0 0x20>;
			rsnges;
			#address-cells = <1>;
			#size-cells = <1>;
			clocks = <&cmu_peric1 CLK_GOUT_PERIC1_TOP1_PCLK_1>,
				 <&cmu_peric1 CLK_GOUT_PERIC1_TOP1_IPCLK_1>;
			clock-names = "pclk", "ipclk";
			samsung,sysreg = <&sysreg_peric1 0x1034>;
			samsung,mode = <USI_MODE_I2C>;
			status = "disabled";

			hsi2c_19: i2c@10910000 {
				compatible = "samsung,exynos990-hsi2c",
					     "samsung,exynosautov9-hsi2c";
				reg = <0x10910000 0xc0>;
				#address-cells = <1>;
				#size-cells = <0>;
				clocks = <&cmu_peric1 CLK_GOUT_PERIC1_TOP1_IPCLK_1>,
					 <&cmu_peric1 CLK_GOUT_PERIC1_TOP1_PCLK_1>;
				clock-names = "hsi2c", "hsi2c_pclk";
				interrupts = <GIC_SPI 424 IRQ_TYPE_LEVEL_HIGH>;
				pinctrl-0 = <&hsi2c19_bus>;
				pinctrl-names = "default";
				status = "disabled";
			};
		};

		usi10: usi@109200c0 {
			compatible = "samsung,exynos990-usi", "samsung,exynos850-usi";
			reg = <0x109200c0 0x20>;
			ranges;
			#address-cells = <1>;
			#size-cells = <1>;
			clocks = <&cmu_peric1 CLK_GOUT_PERIC1_TOP1_PCLK_2>,
				 <&cmu_peric1 CLK_GOUT_PERIC1_TOP1_IPCLK_2>;
			clock-names = "pclk", "ipclk";
			samsung,sysreg = <&sysreg_peric1 0x1038>;
			status = "disabled";

			hsi2c_20: i2c@10920000 {
				compatible = "samsung,exynos990-hsi2c",
					     "samsung,exynosautov9-hsi2c";
				reg = <0x10920000 0xc0>;
				#address-cells = <1>;
				#size-cells = <0>;
				clocks = <&cmu_peric1 CLK_GOUT_PERIC1_TOP1_IPCLK_2>,
					 <&cmu_peric1 CLK_GOUT_PERIC1_TOP1_PCLK_2>;
				clock-names = "hsi2c", "hsi2c_pclk";
				interrupts = <GIC_SPI 427 IRQ_TYPE_LEVEL_HIGH>;
				pinctrl-0 = <&hsi2c20_bus>;
				pinctrl-names = "default";
				status = "disabled";
			};

			serial_12: serial@10920000 {
				compatible = "samsung,exynos990-uart",
					     "samsung,exynos8895-uart";
				reg = <0x10920000 0xc0>;
				clocks = <&cmu_peric1 CLK_GOUT_PERIC1_TOP1_PCLK_2>,
					 <&cmu_peric1 CLK_GOUT_PERIC1_TOP1_IPCLK_2>;
				clock-names = "uart", "clk_uart_baud0";
				interrupts = <GIC_SPI 427 IRQ_TYPE_LEVEL_HIGH>;
				pinctrl-0 = <&uart12_bus_single>;
				pinctrl-names = "default";
				samsung,uart-fifosize = <256>;
				status = "disabled";
			};
		};

		usi_i2c_10: usi@109300c0 {
			compatible = "samsung,exynos990-usi", "samsung,exynos850-usi";
			reg = <0x109300c0 0x20>;
			rsnges;
			#address-cells = <1>;
			#size-cells = <1>;
			clocks = <&cmu_peric1 CLK_GOUT_PERIC1_TOP1_PCLK_3>,
				 <&cmu_peric1 CLK_GOUT_PERIC1_TOP1_IPCLK_3>;
			clock-names = "pclk", "ipclk";
			samsung,sysreg = <&sysreg_peric1 0x103c>;
			samsung,mode = <USI_MODE_I2C>;
			status = "disabled";

			hsi2c_21: i2c@10930000 {
				compatible = "samsung,exynos990-hsi2c",
					     "samsung,exynosautov9-hsi2c";
				reg = <0x10930000 0xc0>;
				#address-cells = <1>;
				#size-cells = <0>;
				clocks = <&cmu_peric1 CLK_GOUT_PERIC1_TOP1_IPCLK_3>,
					 <&cmu_peric1 CLK_GOUT_PERIC1_TOP1_PCLK_3>;
				clock-names = "hsi2c", "hsi2c_pclk";
				interrupts = <GIC_SPI 426 IRQ_TYPE_LEVEL_HIGH>;
				pinctrl-0 = <&hsi2c21_bus>;
				pinctrl-names = "default";
				status = "disabled";
			};
		};

		usi11: usi@109400c0 {
			compatible = "samsung,exynos990-usi", "samsung,exynos850-usi";
			reg = <0x109400c0 0x20>;
			ranges;
			#address-cells = <1>;
			#size-cells = <1>;
			clocks = <&cmu_peric1 CLK_GOUT_PERIC1_TOP1_PCLK_4>,
				 <&cmu_peric1 CLK_GOUT_PERIC1_TOP1_IPCLK_4>;
			clock-names = "pclk", "ipclk";
			samsung,sysreg = <&sysreg_peric1 0x1040>;
			status = "disabled";

			hsi2c_22: i2c@10940000 {
				compatible = "samsung,exynos990-hsi2c",
					     "samsung,exynosautov9-hsi2c";
				reg = <0x10940000 0xc0>;
				#address-cells = <1>;
				#size-cells = <0>;
				clocks = <&cmu_peric1 CLK_GOUT_PERIC1_TOP1_IPCLK_4>,
					 <&cmu_peric1 CLK_GOUT_PERIC1_TOP1_PCLK_4>;
				clock-names = "hsi2c", "hsi2c_pclk";
				interrupts = <GIC_SPI 429 IRQ_TYPE_LEVEL_HIGH>;
				pinctrl-0 = <&hsi2c22_bus>;
				pinctrl-names = "default";
				status = "disabled";
			};

			serial_13: serial@10940000 {
				compatible = "samsung,exynos990-uart",
					     "samsung,exynos8895-uart";
				reg = <0x10940000 0xc0>;
				clocks = <&cmu_peric1 CLK_GOUT_PERIC1_TOP1_PCLK_4>,
					 <&cmu_peric1 CLK_GOUT_PERIC1_TOP1_IPCLK_4>;
				clock-names = "uart", "clk_uart_baud0";
				interrupts = <GIC_SPI 429 IRQ_TYPE_LEVEL_HIGH>;
				pinctrl-0 = <&uart13_bus_single>;
				pinctrl-names = "default";
				samsung,uart-fifosize = <64>;
				status = "disabled";
			};
		};

		usi_i2c_11: usi@109500c0 {
			compatible = "samsung,exynos990-usi", "samsung,exynos850-usi";
			reg = <0x109500c0 0x20>;
			ranges;
			#address-cells = <1>;
			#size-cells = <1>;
			clocks = <&cmu_peric1 CLK_GOUT_PERIC1_TOP1_PCLK_5>,
				 <&cmu_peric1 CLK_GOUT_PERIC1_TOP1_IPCLK_5>;
			clock-names = "pclk", "ipclk";
			samsung,sysreg = <&sysreg_peric1 0x1044>;
			samsung,mode = <USI_MODE_I2C>;
			status = "disabled";

			hsi2c_23: i2c@10950000 {
				compatible = "samsung,exynos990-hsi2c",
					     "samsung,exynosautov9-hsi2c";
				reg = <0x10950000 0xc0>;
				#address-cells = <1>;
				#size-cells = <0>;
				clocks = <&cmu_peric1 CLK_GOUT_PERIC1_TOP1_IPCLK_5>,
					 <&cmu_peric1 CLK_GOUT_PERIC1_TOP1_PCLK_5>;
				clock-names = "hsi2c", "hsi2c_pclk";
				interrupts = <GIC_SPI 428 IRQ_TYPE_LEVEL_HIGH>;
				pinctrl-names = "default";
				pinctrl-0 = <&hsi2c23_bus>;
				status = "disabled";
			};
		};

		usi12: usi@109c00c0 {
			compatible = "samsung,exynos990-usi", "samsung,exynos850-usi";
			reg = <0x109c00c0 0x20>;
			ranges;
			#address-cells = <1>;
			#size-cells = <1>;
			clocks = <&cmu_peric1 CLK_GOUT_PERIC1_TOP1_PCLK_12>,
				 <&cmu_peric1 CLK_GOUT_PERIC1_TOP1_IPCLK_12>;
			clock-names = "pclk", "ipclk";
			samsung,sysreg = <&sysreg_peric1 0x2000>;
			status = "disabled";

			hsi2c_24: i2c@109c0000 {
				compatible = "samsung,exynos990-hsi2c",
					     "samsung,exynosautov9-hsi2c";
				reg = <0x109c0000 0xc0>;
				#address-cells = <1>;
				#size-cells = <0>;
				clocks = <&cmu_peric1 CLK_GOUT_PERIC1_TOP1_IPCLK_12>,
					 <&cmu_peric1 CLK_GOUT_PERIC1_TOP1_PCLK_12>;
				clock-names = "hsi2c", "hsi2c_pclk";
				interrupts = <GIC_SPI 431 IRQ_TYPE_LEVEL_HIGH>;
				pinctrl-0 = <&hsi2c24_bus>;
				pinctrl-names = "default";
				status = "disabled";
			};

			serial_14: serial@109c0000 {
				compatible = "samsung,exynos990-uart",
					     "samsung,exynos8895-uart";
				reg = <0x109c0000 0xc0>;
				clocks = <&cmu_peric1 CLK_GOUT_PERIC1_TOP1_PCLK_12>,
					 <&cmu_peric1 CLK_GOUT_PERIC1_TOP1_IPCLK_12>;
				clock-names = "uart", "clk_uart_baud0";
				interrupts = <GIC_SPI 431 IRQ_TYPE_LEVEL_HIGH>;
				pinctrl-0 = <&uart14_bus_single>;
				pinctrl-names = "default";
				samsung,uart-fifosize = <64>;
				status = "disabled";
			};
		};

		usi_i2c_12: usi@109d00c0 {
			compatible = "samsung,exynos990-usi", "samsung,exynos850-usi";
			reg = <0x109d00c0 0x20>;
			ranges;
			#address-cells = <1>;
			#size-cells = <1>;
			clocks = <&cmu_peric1 CLK_GOUT_PERIC1_TOP1_PCLK_13>,
				 <&cmu_peric1 CLK_GOUT_PERIC1_TOP1_IPCLK_13>;
			clock-names = "pclk", "ipclk";
			samsung,sysreg = <&sysreg_peric1 0x2004>;
			samsung,mode = <USI_MODE_I2C>;
			status = "disabled";

			hsi2c_25: i2c@109d0000 {
				compatible = "samsung,exynos990-hsi2c",
					     "samsung,exynosautov9-hsi2c";
				reg = <0x109d0000 0xc0>;
				#address-cells = <1>;
				#size-cells = <0>;
				clocks = <&cmu_peric1 CLK_GOUT_PERIC1_TOP1_IPCLK_13>,
					 <&cmu_peric1 CLK_GOUT_PERIC1_TOP1_PCLK_13>;
				clock-names = "hsi2c", "hsi2c_pclk";
				interrupts = <GIC_SPI 430 IRQ_TYPE_LEVEL_HIGH>;
				pinctrl-0 = <&hsi2c25_bus>;
				pinctrl-names = "default";
				status = "disabled";
			};
		};

		usi16: usi@109600c0 {
			compatible = "samsung,exynos990-usi", "samsung,exynos850-usi";
			reg = <0x109600c0 0x20>;
			ranges;
			#address-cells = <1>;
			#size-cells = <1>;
			clocks = <&cmu_peric1 CLK_GOUT_PERIC1_TOP1_PCLK_6>,
				 <&cmu_peric1 CLK_GOUT_PERIC1_TOP1_IPCLK_6>;
			clock-names = "pclk", "ipclk";
			samsung,sysreg = <&sysreg_peric1 0x1048>;
			status = "disabled";

			hsi2c_32: i2c@10960000 {
				compatible = "samsung,exynos990-hsi2c",
					     "samsung,exynosautov9-hsi2c";
				reg = <0x10960000 0xc0>;
				#address-cells = <1>;
				#size-cells = <0>;
				clocks = <&cmu_peric1 CLK_GOUT_PERIC1_TOP1_IPCLK_6>,
					 <&cmu_peric1 CLK_GOUT_PERIC1_TOP1_PCLK_6>;
				clock-names = "hsi2c", "hsi2c_pclk";
				interrupts = <GIC_SPI 434 IRQ_TYPE_LEVEL_HIGH>;
				pinctrl-0 = <&hsi2c32_bus>;
				pinctrl-names = "default";
				status = "disabled";
			};

			serial_18: serial@10960000 {
				compatible = "samsung,exynos990-uart",
					     "samsung,exynos8895-uart";
				reg = <0x10960000 0xc0>;
				clocks = <&cmu_peric1 CLK_GOUT_PERIC1_TOP1_PCLK_6>,
					 <&cmu_peric1 CLK_GOUT_PERIC1_TOP1_IPCLK_6>;
				clock-names = "uart", "clk_uart_baud0";
				interrupts = <GIC_SPI 434 IRQ_TYPE_LEVEL_HIGH>;
				pinctrl-0 = <&uart18_bus_single>;
				pinctrl-names = "default";
				samsung,uart-fifosize = <64>;
				status = "disabled";
			};
		};

		usi_i2c_16: usi@109700c0 {
			compatible = "samsung,exynos990-usi", "samsung,exynos850-usi";
			reg = <0x109700c0 0x20>;
			samsung,sysreg = <&sysreg_peric1 0x104c>;
			samsung,mode = <USI_MODE_I2C>;
			#address-cells = <1>;
			#size-cells = <1>;
			ranges;
			clocks = <&cmu_peric1 CLK_GOUT_PERIC1_TOP1_PCLK_7>,
				 <&cmu_peric1 CLK_GOUT_PERIC1_TOP1_IPCLK_7>;
			clock-names = "pclk", "ipclk";
			status = "disabled";

			hsi2c_33: i2c@10970000 {
				compatible = "samsung,exynos990-hsi2c",
					     "samsung,exynosautov9-hsi2c";
				reg = <0x10970000 0xc0>;
				#address-cells = <1>;
				#size-cells = <0>;
				clocks = <&cmu_peric1 CLK_GOUT_PERIC1_TOP1_IPCLK_7>,
					 <&cmu_peric1 CLK_GOUT_PERIC1_TOP1_PCLK_7>;
				clock-names = "hsi2c", "hsi2c_pclk";
				interrupts = <GIC_SPI 432 IRQ_TYPE_LEVEL_HIGH>;
				pinctrl-0 = <&hsi2c33_bus>;
				pinctrl-names = "default";
				status = "disabled";
			};
		};

		usi17: usi@109900c0 {
			compatible = "samsung,exynos990-usi", "samsung,exynos850-usi";
			reg = <0x109900c0 0x20>;
			ranges;
			#address-cells = <1>;
			#size-cells = <1>;
			clocks = <&cmu_peric1 CLK_GOUT_PERIC1_TOP1_PCLK_9>,
				 <&cmu_peric1 CLK_GOUT_PERIC1_TOP1_IPCLK_9>;
			clock-names = "pclk", "ipclk";
			samsung,sysreg = <&sysreg_peric1 0x1050>;
			status = "disabled";

			hsi2c_34: i2c@10990000 {
				compatible = "samsung,exynos990-hsi2c",
					     "samsung,exynosautov9-hsi2c";
				reg = <0x10990000 0xc0>;
				#address-cells = <1>;
				#size-cells = <0>;
				clocks = <&cmu_peric1 CLK_GOUT_PERIC1_TOP1_IPCLK_9>,
					 <&cmu_peric1 CLK_GOUT_PERIC1_TOP1_PCLK_9>;
				clock-names = "hsi2c", "hsi2c_pclk";
				interrupts = <GIC_SPI 437 IRQ_TYPE_LEVEL_HIGH>;
				pinctrl-0 = <&hsi2c34_bus>;
				pinctrl-names = "default";
				status = "disabled";
			};

			serial_19: serial@10990000 {
				compatible = "samsung,exynos990-uart",
					     "samsung,exynos8895-uart";
				reg = <0x10990000 0xc0>;
				clocks = <&cmu_peric1 CLK_GOUT_PERIC1_TOP1_PCLK_9>,
					 <&cmu_peric1 CLK_GOUT_PERIC1_TOP1_IPCLK_9>;
				clock-names = "uart", "clk_uart_baud0";
				interrupts = <GIC_SPI 437 IRQ_TYPE_LEVEL_HIGH>;
				pinctrl-0 = <&uart19_bus_single>;
				pinctrl-names = "default";
				samsung,uart-fifosize = <64>;
				status = "disabled";
			};
		};

		usi_i2c_17: usi@109a00c0 {
			compatible = "samsung,exynos990-usi", "samsung,exynos850-usi";
			reg = <0x109a00c0 0x20>;
			ranges;
			#address-cells = <1>;
			#size-cells = <1>;
			clocks = <&cmu_peric1 CLK_GOUT_PERIC1_TOP1_PCLK_10>,
				 <&cmu_peric1 CLK_GOUT_PERIC1_TOP1_IPCLK_10>;
			clock-names = "pclk", "ipclk";
			samsung,sysreg = <&sysreg_peric1 0x1054>;
			samsung,mode = <USI_MODE_I2C>;
			status = "disabled";

			hsi2c_35: i2c@10990000 {
				compatible = "samsung,exynos990-hsi2c",
					     "samsung,exynosautov9-hsi2c";
				reg = <0x10990000 0xc0>;
				#address-cells = <1>;
				#size-cells = <0>;
				clocks = <&cmu_peric1 CLK_GOUT_PERIC1_TOP1_IPCLK_10>,
					 <&cmu_peric1 CLK_GOUT_PERIC1_TOP1_PCLK_10>;
				clock-names = "hsi2c", "hsi2c_pclk";
				interrupts = <GIC_SPI 435 IRQ_TYPE_LEVEL_HIGH>;
				pinctrl-0 = <&hsi2c35_bus>;
				pinctrl-names = "default";
				status = "disabled";
			};
		};

		usi18: usi@109e00c0 {
			compatible = "samsung,exynos990-usi", "samsung,exynos850-usi";
			reg = <0x109e00c0 0x20>;
			ranges;
			#address-cells = <1>;
			#size-cells = <1>;
			clocks = <&cmu_peric1 CLK_GOUT_PERIC1_TOP1_PCLK_14>,
				 <&cmu_peric1 CLK_GOUT_PERIC1_TOP1_IPCLK_14>;
			clock-names = "pclk", "ipclk";
			samsung,sysreg = <&sysreg_peric1 0x2008>;
			status = "disabled";

			hsi2c_36: i2c@109e0000 {
				compatible = "samsung,exynos990-hsi2c",
					     "samsung,exynosautov9-hsi2c";
				reg = <0x109e0000 0xc0>;
				#address-cells = <1>;
				#size-cells = <0>;
				clocks = <&cmu_peric1 CLK_GOUT_PERIC1_TOP1_IPCLK_14>,
					 <&cmu_peric1 CLK_GOUT_PERIC1_TOP1_PCLK_14>;
				clock-names = "hsi2c", "hsi2c_pclk";
				interrupts = <GIC_SPI 439 IRQ_TYPE_LEVEL_HIGH>;
				pinctrl-0 = <&hsi2c36_bus>;
				pinctrl-names = "default";
				status = "disabled";
			};

			serial_20: serial@109e0000 {
				compatible = "samsung,exynos990-uart",
					     "samsung,exynos8895-uart";
				reg = <0x109e0000 0xc0>;
				clocks = <&cmu_peric1 CLK_GOUT_PERIC1_TOP1_PCLK_14>,
					 <&cmu_peric1 CLK_GOUT_PERIC1_TOP1_IPCLK_14>;
				clock-names = "uart", "clk_uart_baud0";
				interrupts = <GIC_SPI 439 IRQ_TYPE_LEVEL_HIGH>;
				pinctrl-0 = <&uart20_bus_single>;
				pinctrl-names = "default";
				samsung,uart-fifosize = <64>;
				status = "disabled";
			};
		};

		usi_i2c_18: usi@109f00c0 {
			compatible = "samsung,exynos990-usi", "samsung,exynos850-usi";
			reg = <0x109f00c0 0x20>;
			ranges;
			#address-cells = <1>;
			#size-cells = <1>;
			clocks = <&cmu_peric1 CLK_GOUT_PERIC1_TOP1_PCLK_15>,
				 <&cmu_peric1 CLK_GOUT_PERIC1_TOP1_IPCLK_15>;
			clock-names = "pclk", "ipclk";
			samsung,sysreg = <&sysreg_peric1 0x200c>;
			samsung,mode = <USI_MODE_I2C>;
			status = "disabled";

			hsi2c_37: i2c@109f0000 {
				compatible = "samsung,exynos990-hsi2c",
					     "samsung,exynosautov9-hsi2c";
				reg = <0x109f0000 0xc0>;
				#address-cells = <1>;
				#size-cells = <0>;
				clocks = <&cmu_peric1 CLK_GOUT_PERIC1_TOP1_IPCLK_15>,
					 <&cmu_peric1 CLK_GOUT_PERIC1_TOP1_PCLK_15>;
				clock-names = "hsi2c", "hsi2c_pclk";
				interrupts = <GIC_SPI 438 IRQ_TYPE_LEVEL_HIGH>;
				pinctrl-0 = <&hsi2c37_bus>;
				pinctrl-names = "default";
				status = "disabled";
			};
		};

		cmu_hsi0: clock-controller@10a00000 {
			compatible = "samsung,exynos990-cmu-hsi0";
			reg = <0x10a00000 0x8000>;
			#clock-cells = <1>;

			clocks = <&oscclk>,
				 <&cmu_top CLK_DOUT_CMU_HSI0_BUS>,
				 <&cmu_top CLK_DOUT_CMU_HSI0_USB31DRD>,
				 <&cmu_top CLK_DOUT_CMU_HSI0_USBDP_DEBUG>,
				 <&cmu_top CLK_DOUT_CMU_HSI0_DPGTC>;
			clock-names = "oscclk",
				      "bus",
				      "usb31drd",
				      "usbdp_debug",
				      "dpgtc";
		};

		usbdrd_phy: phy@10c00000 {
			compatible = "samsung,exynos990-usbdrd-phy";
			reg = <0x10c00000 0x100>;
			clocks = <&cmu_hsi0 CLK_GOUT_HSI0_USB31DRD_ACLK_PHYCTRL>,
				 <&oscclk>;
			clock-names = "phy", "ref";
			samsung,pmu-syscon = <&pmu_system_controller>;
			#phy-cells = <1>;
			status = "disabled";
		};

		usbdrd: usb@10e00000 {
			compatible = "samsung,exynos990-dwusb3",
				     "samsung,exynos850-dwusb3";
			ranges = <0x0 0x10e00000 0x10000>;
			clocks = <&cmu_hsi0 CLK_GOUT_HSI0_USB31DRD_BUS_CLK_EARLY>,
				 <&cmu_hsi0 CLK_GOUT_HSI0_USB31DRD_USB31DRD_REF_CLK_40>;
			clock-names = "bus_early", "ref";
			#address-cells = <1>;
			#size-cells = <1>;
			status = "disabled";

			usbdrd_dwc3: usb@0 {
				compatible = "snps,dwc3";
				reg = <0x0 0x10000>;
				interrupts = <GIC_SPI 310 IRQ_TYPE_LEVEL_HIGH>;
				phys = <&usbdrd_phy 0>;
				phy-names = "usb2-phy";
			};
		};

		pinctrl_hsi1: pinctrl@13040000 {
			compatible = "samsung,exynos990-pinctrl";
			reg = <0x13040000 0x1000>;
			interrupts = <GIC_SPI 312 IRQ_TYPE_LEVEL_HIGH>;
		};

		pinctrl_hsi2: pinctrl@13c30000 {
			compatible = "samsung,exynos990-pinctrl";
			reg = <0x13c30000 0x1000>;
			interrupts = <GIC_SPI 322 IRQ_TYPE_LEVEL_HIGH>;
		};

		pinctrl_vts: pinctrl@15580000 {
			compatible = "samsung,exynos990-pinctrl";
			reg = <0x15580000 0x1000>;
		};

		pinctrl_alive: pinctrl@15850000 {
			compatible = "samsung,exynos990-pinctrl";
			reg = <0x15850000 0x1000>;

			wakeup-interrupt-controller {
				compatible = "samsung,exynos990-wakeup-eint",
					     "samsung,exynos850-wakeup-eint",
					     "samsung,exynos7-wakeup-eint";
			};
		};

		pmu_system_controller: system-controller@15860000 {
			compatible = "samsung,exynos990-pmu",
				     "samsung,exynos7-pmu", "syscon";
			reg = <0x15860000 0x10000>;

			reboot: syscon-reboot {
				compatible = "syscon-reboot";
				regmap = <&pmu_system_controller>;
				offset = <0x3a00>; /* SWRESET */
				mask = <0x2>; /* SWRESET_TRIGGER */
				value = <0x2>;
			};
		};

		pinctrl_cmgp: pinctrl@15c30000 {
			compatible = "samsung,exynos990-pinctrl";
			reg = <0x15c30000 0x1000>;
		};

		cmu_top: clock-controller@1a330000 {
			compatible = "samsung,exynos990-cmu-top";
			reg = <0x1a330000 0x8000>;
			#clock-cells = <1>;

			clocks = <&oscclk>;
			clock-names = "oscclk";
		};
	};

	timer {
		compatible = "arm,armv8-timer";
		interrupts = <GIC_PPI 13 (GIC_CPU_MASK_SIMPLE(8) | IRQ_TYPE_LEVEL_LOW)>,
			     <GIC_PPI 14 (GIC_CPU_MASK_SIMPLE(8) | IRQ_TYPE_LEVEL_LOW)>,
			     <GIC_PPI 11 (GIC_CPU_MASK_SIMPLE(8) | IRQ_TYPE_LEVEL_LOW)>,
			     <GIC_PPI 10 (GIC_CPU_MASK_SIMPLE(8) | IRQ_TYPE_LEVEL_LOW)>;

		/*
		 * Non-updatable, broken stock Samsung bootloader does not
		 * configure CNTFRQ_EL0
		 */
		clock-frequency = <26000000>;
	};
};

#include "exynos990-pinctrl.dtsi"
